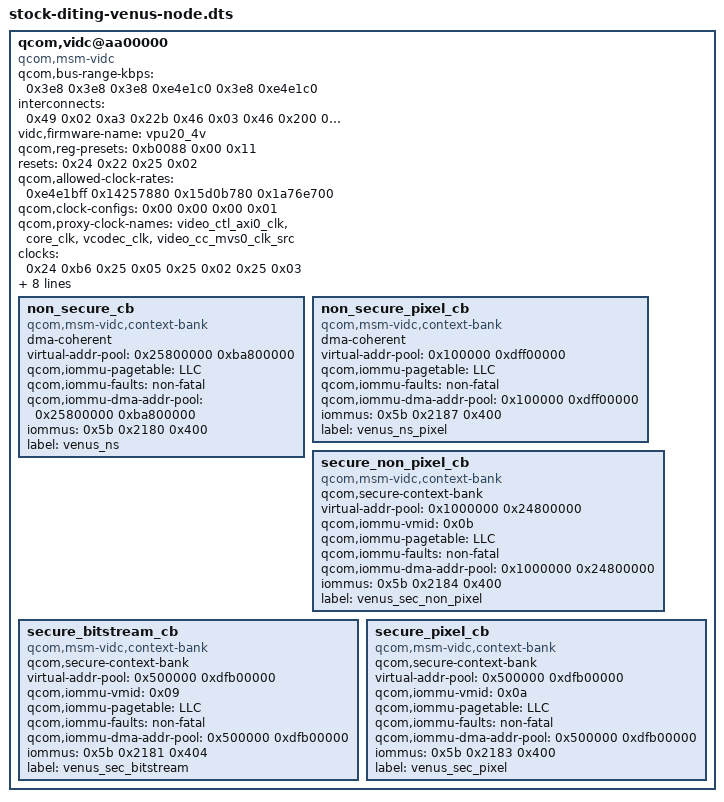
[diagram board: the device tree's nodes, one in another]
		qcom,vidc@aa00000 {
			phandle = <0x4d5>;
			qcom,bus-range-kbps = <0x3e8 0x3e8 0x3e8 0xe4e1c0 0x3e8 0xe4e1c0>;
			interconnects = <0x49 0x02 0xa3 0x22b 0x46 0x03 0x46 0x200 0x342 0x24 0x49 0x235>;
			interconnect-names = "venus-cnoc", "venus-ddr", "venus-llcc";
			vidc,firmware-name = "vpu20_4v";
			qcom,reg-presets = <0xb0088 0x00 0x11>;
			reset-names = "video_axi_reset", "video_core_reset";
			resets = <0x24 0x22 0x25 0x02>;
			qcom,allowed-clock-rates = <0xe4e1bff 0x14257880 0x15d0b780 0x1a76e700>;
			qcom,clock-configs = <0x00 0x00 0x00 0x01>;
			qcom,proxy-clock-names = "video_ctl_axi0_clk", "core_clk", "vcodec_clk", "video_cc_mvs0_clk_src";
			clocks = <0x24 0xb6 0x25 0x05 0x25 0x02 0x25 0x03>;
			clock-ids = <0xb6 0x05 0x02 0x03>;
			clock-names = "video_ctl_axi0_clk", "core_clk", "vcodec_clk", "video_cc_mvs0_clk_src";
			vcodec-supply = <0x274>;
			iris-ctl-supply = <0x36>;
			cache-slice-names = "vidsc0";
			#size-cells = <0x01>;
			#address-cells = <0x01>;
			pas-id = <0x09>;
			memory-region = <0x257>;
			interrupts = <0x00 0xae 0x04>;
			reg = <0xaa00000 0xf0000>;
			status = "okay";
			compatible = "qcom,msm-vidc", "qcom,msm-vidc-waipio", "qcom,msm-vidc-iris2";

			non_secure_cb {
				dma-coherent;
				virtual-addr-pool = <0x25800000 0xba800000>;
				qcom,iommu-pagetable = "LLC";
				qcom,iommu-faults = "non-fatal";
				qcom,iommu-dma-addr-pool = <0x25800000 0xba800000>;
				iommus = <0x5b 0x2180 0x400>;
				label = "venus_ns";
				compatible = "qcom,msm-vidc,context-bank";
			};

			non_secure_pixel_cb {
				dma-coherent;
				virtual-addr-pool = <0x100000 0xdff00000>;
				qcom,iommu-pagetable = "LLC";
				qcom,iommu-faults = "non-fatal";
				qcom,iommu-dma-addr-pool = <0x100000 0xdff00000>;
				iommus = <0x5b 0x2187 0x400>;
				label = "venus_ns_pixel";
				compatible = "qcom,msm-vidc,context-bank";
			};

			secure_non_pixel_cb {
				qcom,secure-context-bank;
				virtual-addr-pool = <0x1000000 0x24800000>;
				qcom,iommu-vmid = <0x0b>;
				qcom,iommu-pagetable = "LLC";
				qcom,iommu-faults = "non-fatal";
				qcom,iommu-dma-addr-pool = <0x1000000 0x24800000>;
				iommus = <0x5b 0x2184 0x400>;
				label = "venus_sec_non_pixel";
				compatible = "qcom,msm-vidc,context-bank";
			};

			secure_bitstream_cb {
				qcom,secure-context-bank;
				virtual-addr-pool = <0x500000 0xdfb00000>;
				qcom,iommu-vmid = <0x09>;
				qcom,iommu-pagetable = "LLC";
				qcom,iommu-faults = "non-fatal";
				qcom,iommu-dma-addr-pool = <0x500000 0xdfb00000>;
				iommus = <0x5b 0x2181 0x404>;
				label = "venus_sec_bitstream";
				compatible = "qcom,msm-vidc,context-bank";
			};

			secure_pixel_cb {
				qcom,secure-context-bank;
				virtual-addr-pool = <0x500000 0xdfb00000>;
				qcom,iommu-vmid = <0x0a>;
				qcom,iommu-pagetable = "LLC";
				qcom,iommu-faults = "non-fatal";
				qcom,iommu-dma-addr-pool = <0x500000 0xdfb00000>;
				iommus = <0x5b 0x2183 0x400>;
				label = "venus_sec_pixel";
				compatible = "qcom,msm-vidc,context-bank";
			};
		};
